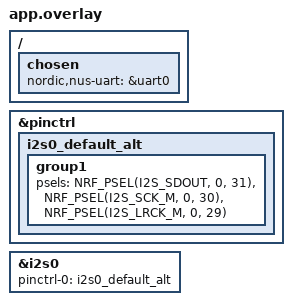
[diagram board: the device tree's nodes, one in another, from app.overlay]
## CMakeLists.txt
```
#---------------------------------------------------------------------------------------------------
#      Copyright (c) 2018 Nordic Semiconductor
# SPDX-License-Identifier: LicenseRef-Nordic-5-Clause
#---------------------------------------------------------------------------------------------------
# Project  : Droid Demo Audio...
#---------------------------------------------------------------------------------------------------
# Date     : 04.10.2023 16:00
# Author   : Datsii Vladislav
# Email    : 3exesh@gmail.com
#---------------------------------------------------------------------------------------------------
#<< COMPILE PARAMS : >>
set(CMAKE_C_CXX_PARAMS_LIST__GLOBAL -std=c++20 -O0  -fpermissive -Wno-unused-variable -Wno-unused-but-set-variable -Wno-unused-parameter -Wno-unused-function )
set(CMAKE_C_CXX_PARAMS_LIST__ZEPHYR -std=c++20 -O0  -fpermissive -isystem -w )
#<< COMPILE PARAMS / >>


cmake_minimum_required(VERSION 3.20.0)
find_package(Zephyr REQUIRED HINTS $ENV{ZEPHYR_BASE})

project(NONE LANGUAGES C CXX)
 
set(CMAKE_CXX_STANDARD 20)
set(CMAKE_CXX_STANDARD_REQUIRED True)
set(CMAKE_CXX_EXTENSIONS OFF)
set(CMAKE_BUILD_TYPE DEBUG)


string(REPLACE ";" " " CMAKE_C_CXX_PARAMS_STR__GLOBAL "${CMAKE_C_CXX_PARAMS_LIST__GLOBAL}")
set(CMAKE_C_FLAGS_DEBUG   "${CMAKE_C_FLAGS_DEBUG}   ${CMAKE_C_CXX_PARAMS_STR__GLOBAL}")
set(CMAKE_CXX_FLAGS_DEBUG "${CMAKE_CXX_FLAGS_DEBUG} ${CMAKE_C_CXX_PARAMS_STR__GLOBAL}")



file(GLOB_RECURSE SRC_DIR_FILES "${CMAKE_SOURCE_DIR}/src/*.c" "${CMAKE_SOURCE_DIR}/src/*.cpp")
STRING(REPLACE "${CMAKE_SOURCE_DIR}/" "" SRC_DIR_FILES "${SRC_DIR_FILES}")
message(STATUS "[ Source files : ]")
foreach(line IN LISTS SRC_DIR_FILES)
    message(STATUS "${line}")
endforeach() 
message(STATUS "")


zephyr_library_compile_options (${CMAKE_C_CXX_PARAMS_LIST__ZEPHYR})
target_sources                 (app PRIVATE ${SRC_DIR_FILES})
target_include_directories     (app PRIVATE "${CMAKE_CURRENT_LIST_DIR}/src")

#target_compile_options (app PRIVATE ${CMAKE_C_CXX_PARAMS_LIST})
#set_target_properties  (app PROPERTIES COMPILE_FLAGS ${CMAKE_C_CXX_PARAMS_LIST})
zephyr_library_include_directories(.)
```

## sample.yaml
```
sample:
  description: Droid Demo Audio
    application
  name: Droid Demo Audio
tests:
  sample.basic.droid_demo_audio:
    tags: cpp
    toolchain_exclude: issm xcc
    integration_platforms:
      - qemu_x86
    harness: console
    harness_config:
      type: multi_line
      regex:
        - "Droid Demo Audio (.*)"
        - "Audio demo project (.*)"
```

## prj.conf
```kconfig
#---------------------------------------------------------------------------------------------------
#      Copyright (c) 2018 Nordic Semiconductor
# SPDX-License-Identifier: LicenseRef-Nordic-5-Clause
#---------------------------------------------------------------------------------------------------
# Project  : Droid Demo Audio
#---------------------------------------------------------------------------------------------------
# Date     : 04.10.2023 16:11
# Author   : Datsii Vladislav
# Email    : 3exesh@gmail.com
#---------------------------------------------------------------------------------------------------


#<< GPIO configuration : >>
CONFIG_GPIO=y
#<< GPIO configuration / >>


#<< LOG : UART : >>
CONFIG_NRFX_UARTE0=y
CONFIG_SERIAL=y
CONFIG_CONSOLE=y
CONFIG_UART_CONSOLE=y
#<< LOG : UART / >>


#<< main() stack size configuration : >>
#CONFIG_MAIN_STACK_SIZE=1024
#<< main() stack size configuration / >>


#<< HEAP configuration : >>
CONFIG_HEAP_MEM_POOL_SIZE=2048
#<< HEAP configuration / >>

#<< I2S configuration : >>
CONFIG_NRFX_I2S=y
CONFIG_I2S=y
CONFIG_I2S_LITEX_RX_BLOCK_COUNT=500
CONFIG_I2S_LITEX_DATA_BIG_ENDIAN=n
#<< I2S configuration / >>


#<< BT configuration : >>
CONFIG_BT=y
CONFIG_BT_PERIPHERAL=y
CONFIG_BT_DEVICE_NAME="Droid_Demo_Audio"
CONFIG_BT_DEVICE_APPEARANCE=833
CONFIG_BT_MAX_CONN=1
CONFIG_BT_MAX_PAIRED=2
#CONFIG_BT_SETTINGS=y
#BT full debug log:
CONFIG_BT_DEBUG_LOG=y
#due to the task (Droid Demo Audio):
CONFIG_BT_LIM_ADV_TIMEOUT=30 
#NUS:
#CONFIG_BT_NUS=y
#BAS:
#CONFIG_BT_BAS=y
#HRS:
#CONFIG_BT_HRS=y
#DIS:
#CONFIG_BT_DIS=y
#PNP:
#CONFIG_BT_DIS_PNP=n
#Security manager protocol:
CONFIG_BT_SMP=y
#<< BT configuration / >>


#<< SoC configuration : >>
CONFIG_FLASH=y
CONFIG_FLASH_PAGE_LAYOUT=y
CONFIG_FLASH_MAP=y
CONFIG_NVS=y
#CONFIG_SETTINGS=y
#<< SoC configuration / >>


#<< DevKit LED Lib configuration : >>
CONFIG_DK_LIBRARY=y
#<< DevKit LED Lib configuration / >>


#<< Zephyr workqueue stack configuration : >>
CONFIG_SYSTEM_WORKQUEUE_STACK_SIZE=2048
#CONFIG_SYSTEM_WORKQUEUE_STACK_SIZE=512
#<< Zephyr workqueue stack configuration / >>


#<< ASSERT configuration : >>
CONFIG_ASSERT=y
CONFIG_ASSERT_TEST=y
CONFIG_ASSERT_LEVEL=2
#<< ASSERT configuration / >>


#<< C++ configuration : >>
CONFIG_CPLUSPLUS=y
CONFIG_STD_CPP20=y
CONFIG_CPP_MAIN=y
#CONFIG_LIB_CPLUSPLUS=y
#CONFIG_GLIBCXX_LIBCPP=y
CONFIG_MINIMAL_LIBC_MALLOC_ARENA_SIZE=128
#<< C++ configuration / >>


#<< LOGGER configuration (Deep info debug mode enabled) : >>
CONFIG_DEBUG=y
CONFIG_DEBUG_INFO=y
CONFIG_LOG=y
CONFIG_LOG_BUFFER_SIZE=4096
CONFIG_LOG_BACKEND_RTT=n
CONFIG_LOG_BACKEND_UART=y
CONFIG_KERNEL_LOG_LEVEL_ERR=y
# Only synchronous logger:
#CONFIG_LOG_MODE_IMMEDIATE=y
#<< LOGGER configuration (Deep info debug mode enabled) / >>

#<< BLUETOOTH : ADITIONAL : >>
# Increased stack due to settings API usage
#CONFIG_BT_SIGNING=y
#CONFIG_BT_ATT_PREPARE_COUNT=5
#CONFIG_BT_IAS=y
#CONFIG_BT_PRIVACY=y

#CONFIG_BT_DEVICE_NAME_DYNAMIC=y
#CONFIG_BT_DEVICE_NAME_MAX=65

#CONFIG_BT_KEYS_OVERWRITE_OLDEST=y
#<< BLUETOOTH : ADITIONAL / >>

#<< BLUETOOTH : NOT USE : >>
#CONFIG_BT_SETTINGS=y
#CONFIG_SETTINGS=y
#<< BLUETOOTH : NOT USE / >>


#<< BLUETOOTH : DYNAMIC GATT SERVERVICES REGISTRATION : >>
CONFIG_BT_GATT_DYNAMIC_DB=y
#<< BLUETOOTH : DYNAMIC GATT SERVERVICES REGISTRATION / >>

#<< BT : FOR TEST : >>
# Example output of thread analyzer
# CONFIG_BT_RX_STACK_SIZE=1024
# CONFIG_BT_CTLR_RX_PRIO_STACK_SIZE=448
# CONFIG_BT_HCI_TX_STACK_SIZE_WITH_PROMPT=y
# CONFIG_BT_HCI_TX_STACK_SIZE=640

# CONFIG_IDLE_STACK_SIZE=128
# CONFIG_MAIN_STACK_SIZE=640
# CONFIG_ISR_STACK_SIZE=1024
# # Reduce Bluetooth buffers
# CONFIG_BT_BUF_EVT_DISCARDABLE_COUNT=1
# CONFIG_BT_BUF_EVT_DISCARDABLE_SIZE=45
# CONFIG_BT_BUF_ACL_RX_COUNT=2
# CONFIG_BT_BUF_EVT_RX_COUNT=2

# CONFIG_BT_CONN_TX_MAX=2
# CONFIG_BT_L2CAP_TX_BUF_COUNT=2
# CONFIG_BT_CTLR_RX_BUFFERS=1
# CONFIG_BT_BUF_ACL_TX_COUNT=3
# CONFIG_BT_BUF_ACL_TX_SIZE=27
#<< BT : FOR TEST / >>
```

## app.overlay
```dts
//-----------------------------------------------------------------------------------------------------------------------------------------------
//      Copyright (c) 2018 Nordic Semiconductor
// SPDX-License-Identifier: LicenseRef-Nordic-5-Clause
//-----------------------------------------------------------------------------------------------------------------------------------------------
// Project  : Droid Demo Audio
//-----------------------------------------------------------------------------------------------------------------------------------------------
// Date     : 04.10.2023 16:18
// Author   : Datsii Vladislav
// Email    : 3exesh@gmail.com
//-----------------------------------------------------------------------------------------------------------------------------------------------
// For more help, browse the DeviceTree documentation at https://docs.zephyrproject.org/latest/guides/dts/index.html
// You can also visit the nRF DeviceTree extension documentation at https://nrfconnect.github.io/vscode-nrf-connect/devicetree/nrfdevicetree.html
//-----------------------------------------------------------------------------------------------------------------------------------------------



//<< DEBUG SEGGER UART : >>
/ {
	chosen {
		nordic,nus-uart = &uart0;
	};
};
//<< DEBUG SEGGER UART / >>

//<< I2S INTERFACE : >>
&pinctrl {
	i2s0_default_alt: i2s0_default_alt {
		group1 {
			psels = <NRF_PSEL(I2S_SDOUT,  0, 31)>,
					<NRF_PSEL(I2S_SCK_M,  0, 30)>,
					<NRF_PSEL(I2S_LRCK_M, 0, 29)>;
					
		};
	};
};

i2s_rxtx: &i2s0 {
	status = "okay";
	pinctrl-0 = <&i2s0_default_alt>;
	pinctrl-names = "default";
};
//<< I2S INTERFACE : >>
```

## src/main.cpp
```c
/**
 ******************************************************************************
 * @file           : main.cpp
 * @brief          : Main program body
 * @author         : Datsii Vladisalav
 * @date           :
 ******************************************************************************
 * @attention
 *
 *  Droid Demo Adudio - nRF52840DK
 *
 ******************************************************************************
 */
#include <zephyr/settings/settings.h>
#include <zephyr/kernel.h>

#include "Llib/periphery/bluetooth/Bluetooth.hpp"
#include "Llib/periphery/i2s/I2s.hpp"
#include "Llib/primitives/audio/Player.hpp"

#include "PlayerControlService.hpp"

#include "sounds/sound_list.hpp"

//<< THREADS : >>
L_THREAD_DEFINE(aduioPlayer_th, 1024, 1, 0, 0);
//<< THREADS / >>

//<< I2S : >>
K_MEM_SLAB_DEFINE_STATIC(i2s_tx_mem_slab, 1024*2*1, 16, 2); // buff*wordWidth*chan
//<< I2S / >>

//<< BLUETOOTH : >>
#define BT_SERVICES_MAXNUM 1
#define BT_ADVERTISINGS_MAXNUM BT_SERVICES_MAXNUM + 1
BluetoothService *btServicesMemory_p[BT_SERVICES_MAXNUM];
bt_data btAdvertisingsMemory_p[BT_ADVERTISINGS_MAXNUM];
//<< BLUETOOTH / >>

int main()
{
    //<< PRESTART : >>

    //<< I2S : >>
    I2s i2s;
    i2s.set(DEVICE_DT_GET(DT_NODELABEL(i2s_rxtx)));
    i2s.setOut(i2s_tx_mem_slab);

    //<< PLAYER : >>
    Player player;
    player.set(aduioPlayer_th);
    player.connect(i2s);

    //<< BLUETOOTH : >>
    Bluetooth::set(btServicesMemory_p, BT_SERVICES_MAXNUM);
    Bluetooth::set(btAdvertisingsMemory_p, BT_ADVERTISINGS_MAXNUM);

    //<< BLUETOOTH : SERVICES : >>
    PlayerControlService PlayerControl_btServ;
    Bluetooth::connect(PlayerControl_btServ);
    PlayerControl_btServ.connect(player);

    //<< INITIALIZATION : >>
    i2s.initOut();
    player.init();
    PlayerControl_btServ.init();
    Bluetooth::init();

    Bluetooth::enable();
    if (IS_ENABLED(CONFIG_SETTINGS)) settings_load();
    Bluetooth::startAdvertising();

    // k_msleep(100);

    // player.soud(sound_OE_Obiymy_8k_st);
    // player.play();

    // while (player.isPlay()) k_msleep(700);

    // player.soud(sound_HARDKISS_ZHiva_16k_st);
    // player.play();

    while (1)
    { // main() have the moust high priority!
        k_msleep(1000);
        __ASM("NOP");
    }
}
```

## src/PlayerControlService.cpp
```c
#include "PlayerControlService.hpp"

#include "sounds/sound_list.hpp"


#include <zephyr/bluetooth/bluetooth.h>
#include <zephyr/bluetooth/conn.h>
#include <zephyr/bluetooth/uuid.h>
#include <zephyr/bluetooth/gatt.h>
#include "Llib/common/log/log.hpp"
#include "Llib/periphery/periphery.hpp"


static const char* printkx_title_str = "PlayerControlService";

//<< BASE STRUCT : DECLARATION : >>
#define BT_UUID_CUSTOM_SERVICE_VAL BT_UUID_128_ENCODE(0x12345678, 0x1234, 0x5678, 0x1234, 0x56789abcdef0)
#define BT_UUID_ENC_SERVICE_VAL    BT_UUID_128_ENCODE(0x12345678, 0x1234, 0x5678, 0x1234, 0x56789abcdef1)
static bt_data     bt_le_ad_header_service    = BT_DATA_BYTES    (BT_DATA_UUID128_ALL, BT_UUID_CUSTOM_SERVICE_VAL);
static bt_uuid_128 bt_lep_prim_service_uuid   = BT_UUID_INIT_128 (BT_UUID_CUSTOM_SERVICE_VAL);
static bt_uuid_128 bt_le_vnd_enc_charact_uuid = BT_UUID_INIT_128 (BT_UUID_ENC_SERVICE_VAL);
//<< BASE STRUCT : DECLARATION / >>


//<< SERVICE : DECLARATION : >>
static bt_gatt_attr playerCtrl_attrs[] = {
        BT_GATT_PRIMARY_SERVICE(&bt_lep_prim_service_uuid),
             BT_GATT_CHARACTERISTIC(&bt_le_vnd_enc_charact_uuid.uuid,
                                   BT_GATT_CHRC_WRITE_WITHOUT_RESP,
                                   BT_GATT_PERM_WRITE, NULL,
                                   NULL, NULL),
};

static bt_gatt_service playerCtrl_svc = BT_GATT_SERVICE(playerCtrl_attrs);
//<< SERVICE : DECLARATION / >>


int PlayerControlService::init(){
    if(_player == NULL){ PRINTKN_ERROR("Player object is not connected", ret); return ps_configError; }
    int ret                                = bt_gatt_service_register(&playerCtrl_svc);
    if(ret){ PRINTKN_ERROR("Failed to create service", ret); return ps_configError; }
    _bt_le_ad_header_service               = bt_le_ad_header_service;
    bt_gatt_attr *vnd_ind_attrvnd_ind_attr = bt_gatt_find_by_uuid(playerCtrl_svc.attrs, playerCtrl_svc.attr_count, &bt_le_vnd_enc_charact_uuid.uuid);
    vnd_ind_attrvnd_ind_attr->write        = get_cmd;
    _tmp_p                                 = this;
    return ps_ok;
}

ssize_t PlayerControlService::get_cmd(bt_conn *conn, const bt_gatt_attr *attr,
                                      const void *buf, uint16_t len, 
                                      uint16_t offset, uint8_t flags){
    if(offset + len > 1) return BT_GATT_ERR(BT_ATT_ERR_INVALID_OFFSET);

    printk("[Command] len    : %d\n",len);
    printk("[Command] offset : %d\n",offset);
    printk("[Command] value  : %d\n",*((uint8_t*)buf));

    switch (*((uint8_t*)buf))
    {
        case 1:
            if(_tmp_p->_player->isPlay()) break;
            _tmp_p->_player->soud(sound_OE_Obiymy_8k_st);
            _tmp_p->_player->play();
            break;
        case 2:
            if(_tmp_p->_player->isPlay()) break;
            _tmp_p->_player->soud(sound_HARDKISS_ZHiva_16k_st);
            //_tmp_p->_player->soud(sound_MIW_Masterpice_16k_st);
            _tmp_p->_player->play();
            break;
        case 3:
            _tmp_p->_player->stop();
            break;
        default:
            break;
    }
    return len;
}
```

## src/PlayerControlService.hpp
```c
/**
  ******************************************************************************
  * @file           : PlayerControlService.hpp
  * @brief          :
  * @author         : Datsii Vladisalav
  * @date           :
  ******************************************************************************
  * @attention
  *
  *  Droid Demo Adudio - nRF52840DK 
  *
  ******************************************************************************
  */

#ifndef PLAYER_CONTROL_SERVICE_HPP_
#define PLAYER_CONTROL_SERVICE_HPP_
#include <zephyr/bluetooth/gatt.h>
#include "Llib/common/interfaces/BluetoothService.hpp"
#include "Llib/primitives/audio/Player.hpp"

#include "sounds/sound_list.hpp"

class PlayerControlService : public BluetoothService{
public:
           int     init();
           void    connect(Player& player) {_player = &player;}
    static ssize_t get_cmd(bt_conn *conn, const  bt_gatt_attr *attr,
                          const void *buf, uint16_t len, 
                    uint16_t offset, uint8_t flags);
private:
                  Player*               _player = NULL;
    static inline PlayerControlService* _tmp_p  = NULL;;
};

#endif // PLAYER_CONTROL_SERVICE_HPP_
```
